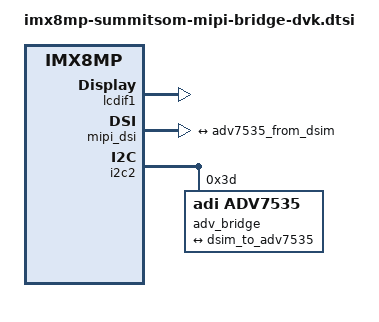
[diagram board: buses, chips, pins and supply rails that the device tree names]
// SPDX-License-Identifier: (GPL-2.0+ OR MIT)
/*
 * Copyright 2021 Laird Connectivity
 */

/* For MIPI to HDMI bridge */

&lcdif1 {
	status = "okay";
};

&mipi_dsi {
	status = "okay";

	port@1 {
		dsim_to_adv7535: endpoint {
			remote-endpoint = <&adv7535_from_dsim>;
			attach-bridge;
		};
	};
};

&i2c2 {
	adv_bridge: adv7535@3d {
		compatible = "adi,adv7535";
		reg = <0x3d>;
		adi,addr-cec = <0x3b>;
		adi,dsi-lanes = <4>;
		status = "okay";

		port {
			adv7535_from_dsim: endpoint {
				remote-endpoint = <&dsim_to_adv7535>;
			};
		};
	};
};
